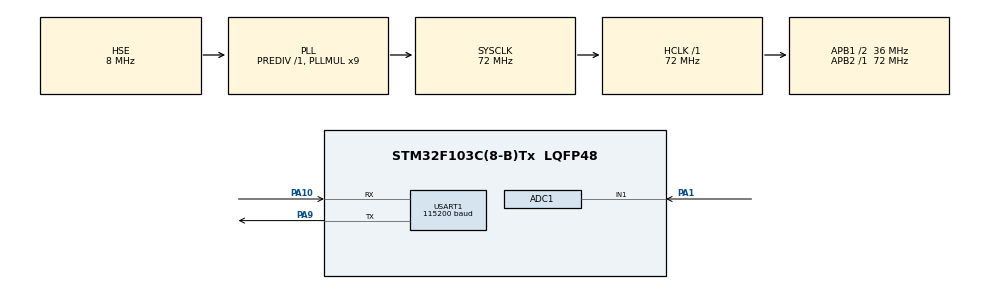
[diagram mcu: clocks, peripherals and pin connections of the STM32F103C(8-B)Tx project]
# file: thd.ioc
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ADC1.Channel-0\#ChannelRegularConversion=ADC_CHANNEL_1
ADC1.ContinuousConvMode=ENABLE
ADC1.NbrOfConversionFlag=1
ADC1.Rank-0\#ChannelRegularConversion=1
ADC1.SamplingTime-0\#ChannelRegularConversion=ADC_SAMPLETIME_1CYCLE_5
ADC1.master=1
Dma.ADC1.0.Direction=DMA_PERIPH_TO_MEMORY
Dma.ADC1.0.Instance=DMA1_Channel1
Dma.ADC1.0.MemDataAlignment=DMA_MDATAALIGN_WORD
Dma.ADC1.0.MemInc=DMA_MINC_ENABLE
Dma.ADC1.0.Mode=DMA_CIRCULAR
Dma.ADC1.0.PeriphDataAlignment=DMA_PDATAALIGN_WORD
Dma.ADC1.0.PeriphInc=DMA_PINC_DISABLE
Dma.ADC1.0.Priority=DMA_PRIORITY_HIGH
Dma.Request0=ADC1
Mcu.Family=STM32F1
Mcu.Name=STM32F103C(8-B)Tx
Mcu.Package=LQFP48
NVIC.ADC1_2_IRQn=true\:0\:0\:false\:false\:true\:true\:true\:true
NVIC.DMA1_Channel1_IRQn=true\:0\:0\:false\:false\:true\:false\:true\:true
NVIC.PriorityGroup=NVIC_PRIORITYGROUP_4
NVIC.USART1_IRQn=true\:0\:0\:false\:false\:true\:true\:true\:true
PA1.Signal=ADCx_IN1
PA10.Mode=Asynchronous
PA10.Signal=USART1_RX
PA9.Mode=Asynchronous
PA9.Signal=USART1_TX
PC14-OSC32_IN.Mode=LSE-External-Oscillator
PC14-OSC32_IN.Signal=RCC_OSC32_IN
PC15-OSC32_OUT.Mode=LSE-External-Oscillator
PC15-OSC32_OUT.Signal=RCC_OSC32_OUT
PD0-OSC_IN.Mode=HSE-External-Oscillator
PD0-OSC_IN.Signal=RCC_OSC_IN
PD1-OSC_OUT.Mode=HSE-External-Oscillator
PD1-OSC_OUT.Signal=RCC_OSC_OUT
ProjectManager.HeapSize=0x200
ProjectManager.StackSize=0x400
ProjectManager.TargetToolchain=Makefile
RCC.ADCPresc=RCC_ADCPCLK2_DIV6
RCC.AHBFreq_Value=72000000
RCC.APB1CLKDivider=RCC_HCLK_DIV2
RCC.APB1Freq_Value=36000000
RCC.APB1TimFreq_Value=72000000
RCC.APB2Freq_Value=72000000
RCC.APB2TimFreq_Value=72000000
RCC.HCLKFreq_Value=72000000
RCC.PLLMUL=RCC_PLL_MUL9
RCC.PLLSourceVirtual=RCC_PLLSOURCE_HSE
RCC.SYSCLKFreq_VALUE=72000000
RCC.SYSCLKSource=RCC_SYSCLKSOURCE_PLLCLK
RCC.USBFreq_Value=72000000
SH.ADCx_IN1.0=ADC1_IN1,IN1
USART1.BaudRate=115200
USART1.VirtualMode=VM_ASYNC
VP_SYS_VS_ND.Mode=No_Debug
board=custom

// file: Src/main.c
/* USER CODE BEGIN Header */
/**
  ******************************************************************************
  * @file           : main.c
  * @brief          : Main program body
  ******************************************************************************
  * @attention
  *
  * Copyright (c) 2024 STMicroelectronics.
  * All rights reserved.
  *
  * This software is licensed under terms that can be found in the LICENSE file
  * in the root directory of this software component.
  * If no LICENSE file comes with this software, it is provided AS-IS.
  *
  ******************************************************************************
  */
/* USER CODE END Header */
#include "main.h"
#include "adc.h"
#include "dma.h"
#include "usart.h"
#include "gpio.h"

/* USER CODE BEGIN Includes */
#include "fft.h"
#include <stdio.h>
#include <stdarg.h>
#include <string.h>
// #include "fft.h"
/* USER CODE END Includes */

/* USER CODE BEGIN PD */
#define ADC_SAMPLE_FREQ           (12000000 / (12.5 + 1.5))
#define ADC_BUFFER_LENGTH         FFT_N
/* USER CODE END PD */

/* USER CODE BEGIN PV */
double signal_freq;
complex_t fft_calc_buffer[FFT_N];

u8  adc_convert_done;
u32 adc_buffer_rd_index;
u32 adc_buffer_wr_index;
u32 adc_buffer[2][ADC_BUFFER_LENGTH];
/* USER CODE END PV */

void SystemClock_Config(void);
/* USER CODE BEGIN PFP */
#ifdef __GNUC__
#define PUTCHAR_PROTOTYPE int __io_putchar(int ch)
#else
#define PUTCHAR_PROTOTYPE int fputc(int ch, FILE *f)
#endif
/* USER CODE END PFP */

/* USER CODE BEGIN 0 */
PUTCHAR_PROTOTYPE
{
    HAL_UART_Transmit(&huart1 , (uint8_t *)&ch, 1, 0xFFFF);
    return ch;
}

void HAL_ADC_ConvCpltCallback(ADC_HandleTypeDef* hadc)
{
    adc_convert_done = 1;
    HAL_ADC_Stop_DMA(hadc);
}
/* USER CODE END 0 */

int main(void)
{

  /* USER CODE BEGIN 1 */
  // 初始化 SIN_TABLE
  fft_init();
  // 初始胡 ADC 读写缓冲区指针
  adc_buffer_wr_index = 0;
  adc_buffer_rd_index = 1;
  /* USER CODE END 1 */

  /* MCU Configuration--------------------------------------------------------*/

  /* Reset of all peripherals, Initializes the Flash interface and the Systick. */
  HAL_Init();

  /* Configure the system clock */
  SystemClock_Config();

  /* Initialize all configured peripherals */
  MX_GPIO_Init();
  MX_DMA_Init();
  MX_ADC1_Init();
  MX_USART1_UART_Init();
  /* USER CODE BEGIN 2 */
  HAL_ADCEx_Calibration_Start(&hadc1);
  HAL_ADC_Start_DMA(&hadc1, adc_buffer[adc_buffer_wr_index], ADC_BUFFER_LENGTH);
  /* USER CODE END 2 */

  /* Infinite loop */
  /* USER CODE BEGIN WHILE */
  while (1)
  {
		if(adc_convert_done)
    {
      // 清除中断标志
      adc_convert_done = 0;
      // 启动 DMA
      adc_buffer_wr_index = adc_buffer_wr_index ? 0 : 1;
      adc_buffer_rd_index = adc_buffer_rd_index ? 0 : 1;
      HAL_ADC_Start_DMA(&hadc1, adc_buffer[adc_buffer_wr_index], ADC_BUFFER_LENGTH);
      // ADC 电压转换
      for(u32 i = 0; i < ADC_BUFFER_LENGTH; i++)
      {
        adc_buffer[adc_buffer_rd_index][i] = (adc_buffer[adc_buffer_rd_index][i] * 3300) >> 12;
      }
      // FFT 计算
      for(u32 i = 0; i < FFT_N; i++)
      {
          fft_calc_buffer[i].real = adc_buffer[adc_buffer_rd_index][i];
          fft_calc_buffer[i].imag = 0;
      }
      signal_freq = fft_calculate(fft_calc_buffer, ADC_SAMPLE_FREQ);
      // 发送数据至上位机
      printf("FREQ:%d\r\n", (int)signal_freq);
      for(u32 i = 0; i < ADC_BUFFER_LENGTH; i++)
      {
        printf("%d,%d\r\n", (int)adc_buffer[adc_buffer_rd_index][i], (i > ADC_BUFFER_LENGTH / 2 - 1) ? 0 : (int)(fabs(fft_calc_buffer[i].real)));
      }
    }
    /* USER CODE END WHILE */

  }
}

void SystemClock_Config(void)
{
  RCC_OscInitTypeDef RCC_OscInitStruct = {0};
  RCC_ClkInitTypeDef RCC_ClkInitStruct = {0};
  RCC_PeriphCLKInitTypeDef PeriphClkInit = {0};

  /** Initializes the RCC Oscillators according to the specified parameters
  * in the RCC_OscInitTypeDef structure.
  */
  RCC_OscInitStruct.OscillatorType = RCC_OSCILLATORTYPE_HSE;
  RCC_OscInitStruct.HSEState = RCC_HSE_ON;
  RCC_OscInitStruct.HSEPredivValue = RCC_HSE_PREDIV_DIV1;
  RCC_OscInitStruct.HSIState = RCC_HSI_ON;
  RCC_OscInitStruct.PLL.PLLState = RCC_PLL_ON;
  RCC_OscInitStruct.PLL.PLLSource = RCC_PLLSOURCE_HSE;
  RCC_OscInitStruct.PLL.PLLMUL = RCC_PLL_MUL9;
  if (HAL_RCC_OscConfig(&RCC_OscInitStruct) != HAL_OK)
  {
    Error_Handler();
  }

  /** Initializes the CPU, AHB and APB buses clocks
  */
  RCC_ClkInitStruct.ClockType = RCC_CLOCKTYPE_HCLK|RCC_CLOCKTYPE_SYSCLK
                              |RCC_CLOCKTYPE_PCLK1|RCC_CLOCKTYPE_PCLK2;
  RCC_ClkInitStruct.SYSCLKSource = RCC_SYSCLKSOURCE_PLLCLK;
  RCC_ClkInitStruct.AHBCLKDivider = RCC_SYSCLK_DIV1;
  RCC_ClkInitStruct.APB1CLKDivider = RCC_HCLK_DIV2;
  RCC_ClkInitStruct.APB2CLKDivider = RCC_HCLK_DIV1;

  if (HAL_RCC_ClockConfig(&RCC_ClkInitStruct, FLASH_LATENCY_2) != HAL_OK)
  {
    Error_Handler();
  }
  PeriphClkInit.PeriphClockSelection = RCC_PERIPHCLK_ADC;
  PeriphClkInit.AdcClockSelection = RCC_ADCPCLK2_DIV6;
  if (HAL_RCCEx_PeriphCLKConfig(&PeriphClkInit) != HAL_OK)
  {
    Error_Handler();
  }
}

void Error_Handler(void)
{
  __disable_irq();
  while (1)
  {
  }
}
